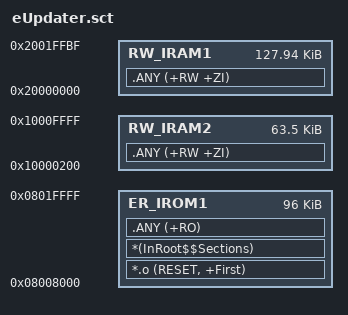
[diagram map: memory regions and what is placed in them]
; Copyright (C) 2011 Department of Robotics Brain and Cognitive Sciences - Istituto Italiano di Tecnologia
; Author:  Marco Accame
; email:   marco.accame@iit.it
; website: www.robotcub.org
; Permission is granted to copy, distribute, and/or modify this program
; under the terms of the GNU General Public License, version 2 or any
; later version published by the Free Software Foundation.
;
; A copy of the license can be found at
; http://www.robotcub.org/icub/license/gpl.txt
;
; This program is distributed in the hope that it will be useful, but
; WITHOUT ANY WARRANTY; without even the implied warranty of
; MERCHANTABILITY or FITNESS FOR A PARTICULAR PURPOSE. See the GNU General
; Public License for more details


LR_IROM1 0x08008000 0x00018000  {    ; load region size_region
  ER_IROM1 0x08008000 0x00018000  {  ; load address = execution address
   *.o (RESET, +First)
   *(InRoot$$Sections)
   .ANY (+RO)
  }
  RW_IRAM1 0x20000000 0x1FFC0  {    ; RW data - memory hole of 064B on top for ipc
   .ANY (+RW +ZI)
  }
  RW_IRAM2 0x10000200 0xFE00  {     ; RW data - memory hole of 512B at start for fatal error on restart 
   .ANY (+RW +ZI)
  } 
} 


